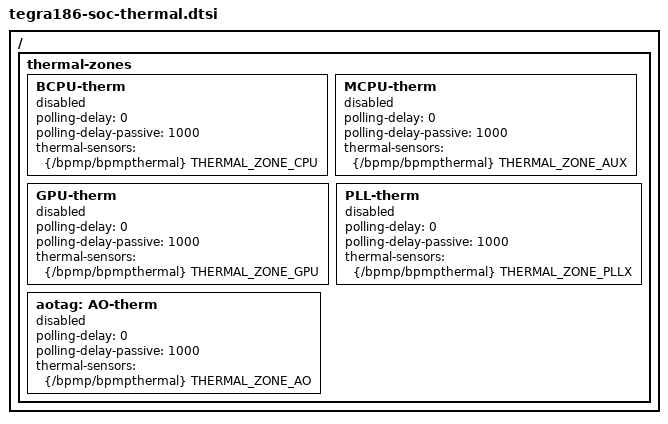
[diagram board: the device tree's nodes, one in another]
/*
 * Copyright (c) 2015, NVIDIA CORPORATION.  All rights reserved.
 *
 * This program is free software; you can redistribute it and/or modify
 * it under the terms of the GNU General Public License as published by
 * the Free Software Foundation; version 2 of the License.
 *
 * This program is distributed in the hope that it will be useful, but WITHOUT
 * ANY WARRANTY; without even the implied warranty of MERCHANTABILITY or
 * FITNESS FOR A PARTICULAR PURPOSE.  See the GNU General Public License for
 * more details.
 *
 * You should have received a copy of the GNU General Public License along
 * with this program; if not, write to the Free Software Foundation, Inc.,
 * 51 Franklin Street, Fifth Floor, Boston, MA  02110-1301, USA.
 *
 */
#include "dt-bindings/thermal/tegra186-thermal.h"

/ {
	thermal-zones {
		BCPU-therm {
			polling-delay = <0>;
			polling-delay-passive = <1000>;
			thermal-sensors = <&{/bpmp/bpmpthermal} THERMAL_ZONE_CPU>;
			status = "disabled";
		};

		MCPU-therm {
			polling-delay = <0>;
			polling-delay-passive = <1000>;
			thermal-sensors = <&{/bpmp/bpmpthermal} THERMAL_ZONE_AUX>;
			status = "disabled";
		};

		GPU-therm {
			polling-delay = <0>;
			polling-delay-passive = <1000>;
			thermal-sensors = <&{/bpmp/bpmpthermal} THERMAL_ZONE_GPU>;
			status = "disabled";
		};

		PLL-therm {
			polling-delay = <0>;
			polling-delay-passive = <1000>;
			thermal-sensors = <&{/bpmp/bpmpthermal} THERMAL_ZONE_PLLX>;
			status = "disabled";
		};

		aotag: AO-therm {
			polling-delay = <0>;
			polling-delay-passive = <1000>;
			thermal-sensors = <&{/bpmp/bpmpthermal} THERMAL_ZONE_AO>;
			status = "disabled";
		};
	};
};
